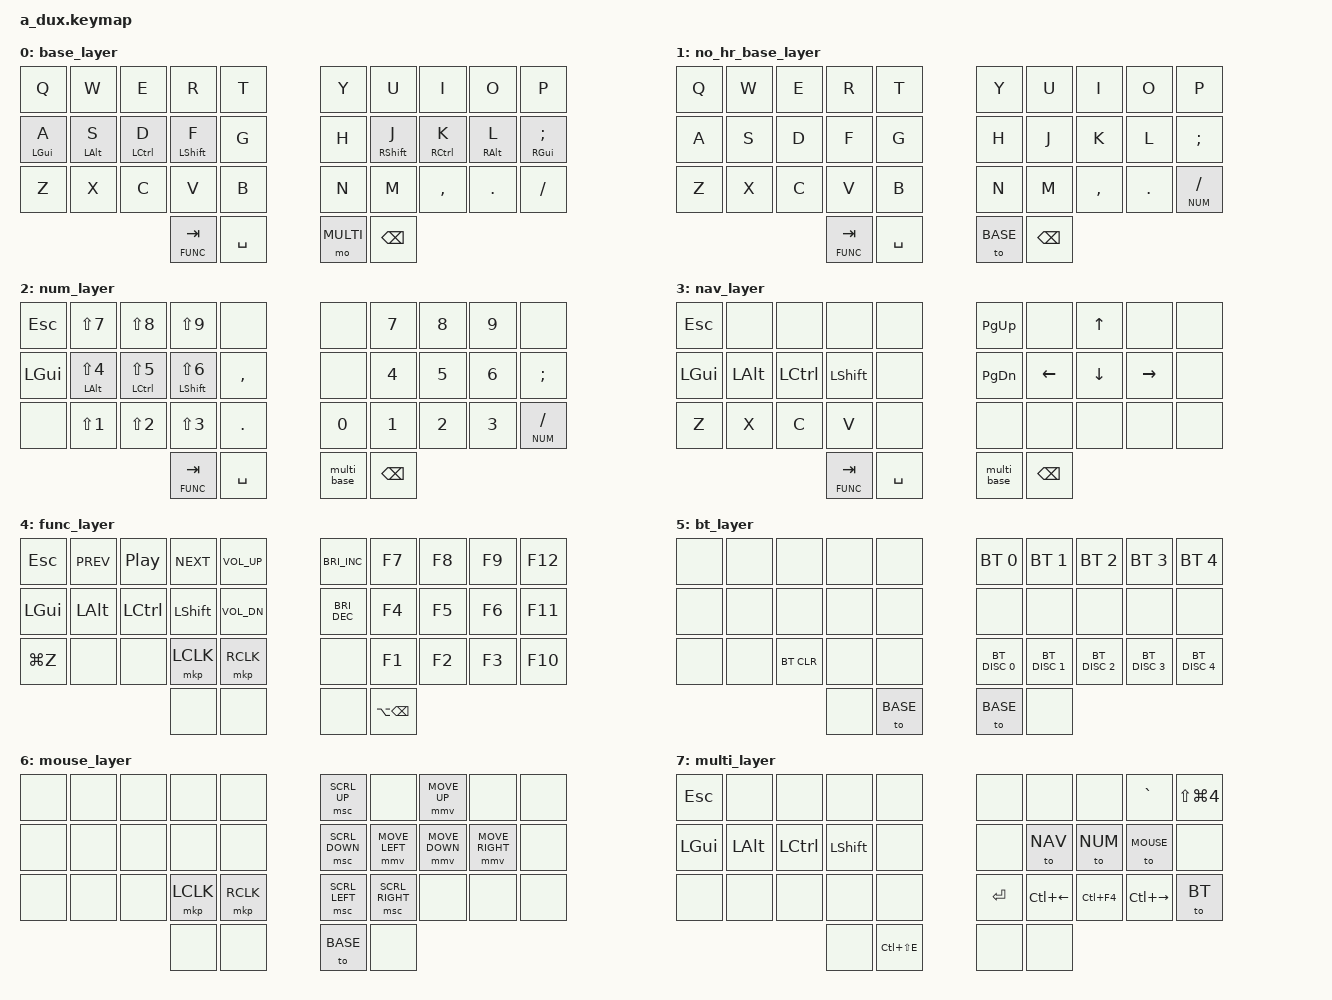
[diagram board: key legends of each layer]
/*
 * Copyright (c) 2021 The ZMK Contributors
 *
 * SPDX-License-Identifier: MIT
 */

#include <behaviors.dtsi>
#include <dt-bindings/zmk/keys.h>
#include <dt-bindings/zmk/bt.h>
#include <dt-bindings/zmk/pointing.h>

// Layers
#define BASE 0
#define NO_HR_BASE 1
#define NUM  2
#define NAV  3
#define FUNC 4
#define BT 5
#define MOUSE 6
#define MULTI 7

/ {
    behaviors {
        hm: homerow_mods {
            compatible = "zmk,behavior-hold-tap";
            #binding-cells = <2>;
            tapping-term-ms = <200>;
            quick-tap-ms = <150>;
            require-prior-idle-ms = <70>;
            flavor = "tap-preferred";
            bindings = <&kp>, <&kp>;
        };
        ht_lk: hold_tap_layer_key {
            compatible = "zmk,behavior-hold-tap";
            #binding-cells = <2>;
            tapping-term-ms = <200>;
            flavor = "hold-preferred";
            bindings = <&mo>, <&kp>;
        };
    };

    macros {
        // hold -> MULTI momentary over BASE; release -> land on BASE (not the layer pressed from)
        multi_base: multi_base {
            compatible = "zmk,behavior-macro";
            #binding-cells = <0>;
            bindings
                = <&to BASE>
                , <&macro_press &mo MULTI>
                , <&macro_pause_for_release>
                , <&macro_release &mo MULTI>;
        };
    };

    combos {
        compatible = "zmk,combos";
        combo_ESC {
            timeout-ms = <50>;
            require-prior-idle-ms = <150>;
            key-positions = <0 1>;
            bindings = <&kp ESC>;
            layers = <BASE NUM NAV NO_HR_BASE>;
        };
        combo_DELETE {
            timeout-ms = <50>;
            require-prior-idle-ms = <150>;
            key-positions = <8 9>;
            bindings = <&kp DEL>;
            layers = <BASE NUM NAV>;
        };
        combo_PLUS_EQ {
            timeout-ms = <50>;
            key-positions = <5 15>;
            bindings = <&kp EQUAL>;
            layers = <BASE NUM>;
        };
        combo_MINUS {
            timeout-ms = <50>;
            key-positions = <15 25>;
            bindings = <&kp MINUS>;
            layers = <BASE NUM>;
        };
        combo_SINGLE_QUOTE {
            timeout-ms = <50>;
            key-positions = <8 18>;
            bindings = <&kp SINGLE_QUOTE>;
            layers = <BASE>;
        };
        combo_LBRACKET {
            timeout-ms = <50>;
            require-prior-idle-ms = <100>;
            key-positions = <16 17>;
            bindings = <&kp LEFT_BRACKET>;
            layers = <BASE NUM>;
        };
        combo_RBRACKET {
            timeout-ms = <50>;
            require-prior-idle-ms = <100>;
            key-positions = <17 18>;
            bindings = <&kp RIGHT_BRACKET>;
            layers = <BASE NUM>;
        };
        combo_BACKSLASH {
            timeout-ms = <50>;
            key-positions = <18 19>;
            bindings = <&kp BACKSLASH>;
            layers = <BASE>;
        };
        combo_LEFT_PARENTHESIS {
            timeout-ms = <50>;
            require-prior-idle-ms = <100>;
            key-positions = <6 7>;
            bindings = <&kp LEFT_PARENTHESIS>;
            layers = <BASE NUM>;
        };
        combo_RIGHT_PARENTHESIS {
            timeout-ms = <50>;
            require-prior-idle-ms = <100>;
            key-positions = <7 8>;
            bindings = <&kp RIGHT_PARENTHESIS>;
            layers = <BASE NUM>;
        };
        combo_DOT {
            timeout-ms = <50>;
            key-positions = <27 28>;
            bindings = <&kp KP_DOT>;
            layers = <BASE NUM>;
        };
        combo_MOVE_TO_NoHomeRowLayer {
            timeout-ms = <50>;
            key-positions = <1 4>;
            require-prior-idle-ms = <200>;
            bindings = <&to NO_HR_BASE>;
            layers = <BASE>;
        };
        combo_CAPS_WORD {
            timeout-ms = <50>;
            key-positions = <13 16>;
            require-prior-idle-ms = <200>;
            bindings = <&caps_word>;
            layers = <BASE>;
        };
        combo_BT_LAYER {
            timeout-ms = <50>;
            key-positions = <20 24>;
            require-prior-idle-ms = <200>;
            bindings = <&to BT>;
            layers = <BASE>;
        };
        combo_BT_CLEAR_ALL {
            timeout-ms = <50>;
            key-positions = <22 24>;
            require-prior-idle-ms = <200>;
            bindings = <&bt BT_CLR_ALL>;
            layers = <BT>;
        };
        combo_NUM_ZERO {
            timeout-ms = <50>;
            key-positions = <26 28>;
            require-prior-idle-ms = <200>;
            bindings = <&kp N0>;
            layers = <NUM>;
        };

    };

    keymap {
        compatible = "zmk,keymap";

        base_layer {
            bindings = <
                &kp Q      &kp W      &kp E       &kp R        &kp T            &kp Y   &kp U        &kp I       &kp O      &kp P
                &hm LGUI A &hm LALT S &hm LCTRL D &hm LSHFT F  &kp G            &kp H   &hm RSHFT J  &hm RCTRL K &hm RALT L &hm RGUI SEMI
                &kp Z      &kp X      &kp C       &kp V        &kp B            &kp N   &kp M        &kp COMMA   &kp DOT    &kp SLASH
                                              &ht_lk FUNC TAB   &kp SPACE     &mo MULTI &kp BSPC
            >;
        };

        no_hr_base_layer {
            bindings = <
                &kp Q   &kp W   &kp E   &kp R   &kp T           &kp Y   &kp U   &kp I       &kp O   &kp P
                &kp A   &kp S   &kp D   &kp F   &kp G           &kp H   &kp J   &kp K       &kp L   &kp SEMI
                &kp Z   &kp X   &kp C   &kp V   &kp B           &kp N   &kp M   &kp COMMA   &kp DOT &lt NUM SLASH
                              &ht_lk FUNC TAB  &kp SPACE     &to BASE   &kp BSPC
            >;
        };

        num_layer {
            bindings = <
                &kp ESC  &kp LS(N7)     &kp LS(N8)      &kp LS(N9)      &none           &none   &kp N7  &kp N8  &kp N9  &none
                &kp LGUI &hm LALT LS(N4)&hm LCTRL LS(N5)&hm LSHFT LS(N6)&kp COMMA       &none   &kp N4  &kp N5  &kp N6  &kp SEMI
                &none    &kp LS(N1)     &kp LS(N2)      &kp LS(N3)      &kp DOT         &kp N0  &kp N1  &kp N2  &kp N3  &lt NUM SLASH
                                                        &ht_lk FUNC TAB  &kp SPACE    &multi_base  &kp BSPC
            >;
        };

        nav_layer {
            bindings = <
                &kp ESC   &none      &none      &none      &none          &kp PG_UP &none     &kp UP   &none     &none
                &kp LGUI  &kp LALT   &kp LCTRL  &kp LSHFT  &none          &kp PG_DN &kp LEFT  &kp DOWN &kp RIGHT &none
                &kp Z      &kp X     &kp C      &kp V      &none          &none     &none     &none    &none     &none
                                        &ht_lk FUNC TAB  &kp SPACE       &multi_base  &kp BSPC
            >;
        };

        func_layer {
            bindings = <
                &kp ESC   &kp C_PREV &kp C_PP  &kp C_NEXT  &kp C_VOL_UP          &kp C_BRI_INC &kp F7     &kp F8     &kp F9     &kp F12
                &kp LGUI  &kp LALT   &kp LCTRL &kp LSHFT   &kp C_VOL_DN          &kp C_BRI_DEC &kp F4     &kp F5     &kp F6     &kp F11
                &kp LG(Z) &none      &none     &mkp LCLK   &mkp RCLK             &none         &kp F1     &kp F2     &kp F3     &kp F10
                                                            &none   &none      &none  &kp LA(BSPC)
            >;
        };

        bt_layer {
            bindings = <
                &none &none &none       &none &none        &bt BT_SEL 0  &bt BT_SEL 1  &bt BT_SEL 2  &bt BT_SEL 3  &bt BT_SEL 4
                &none &none &none       &none &none        &none         &none         &none         &none         &none
                &none &none &bt BT_CLR  &none &none        &bt BT_DISC 0 &bt BT_DISC 1 &bt BT_DISC 2 &bt BT_DISC 3 &bt BT_DISC 4
                                     &none   &to BASE    &to BASE   &none
            >;
        };

        mouse_layer {
            bindings = <
                &none   &none   &none   &none     &none           &msc SCRL_UP   &none           &mmv MOVE_UP   &none           &none
                &none   &none   &none   &none     &none           &msc SCRL_DOWN &mmv MOVE_LEFT  &mmv MOVE_DOWN &mmv MOVE_RIGHT &none
                &none   &none   &none   &mkp LCLK &mkp RCLK       &msc SCRL_LEFT &msc SCRL_RIGHT &none   &none &none
                                               &none  &none     &to BASE &none
            >;
        };

        multi_layer {
            bindings = <
                &kp ESC    &none      &none      &none      &none        &none     &none        &none      &kp GRAVE     &kp LS(LG(N4))
                &kp LGUI   &kp LALT   &kp LCTRL  &kp LSHFT  &none        &none     &to NAV      &to NUM    &to MOUSE     &none
                &none      &none      &none      &none      &none        &kp ENTER &kp LC(LEFT) &kp LC(F4) &kp LC(RIGHT) &to BT
                                                &none   &kp LC(LS(E))  &none   &none
            >;
        };

    };
};
